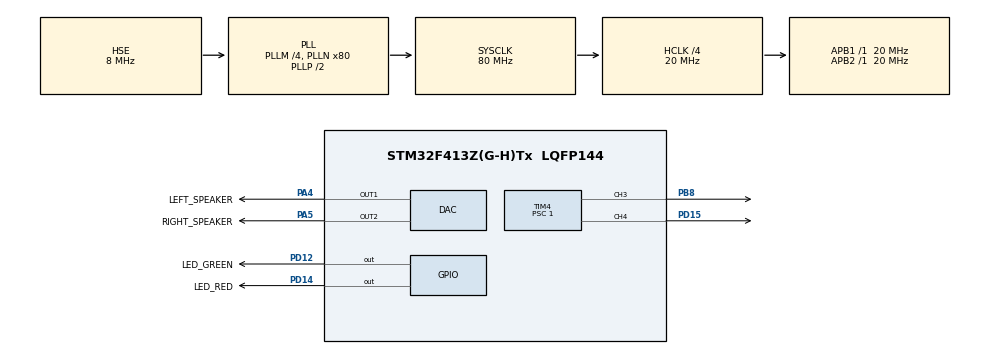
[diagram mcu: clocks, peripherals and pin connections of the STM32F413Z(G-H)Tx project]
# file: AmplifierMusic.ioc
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DAC.DAC_OutputBuffer=DAC_OUTPUTBUFFER_ENABLE
DAC.DAC_Trigger=DAC_TRIGGER_T2_TRGO
DAC.DAC_Trigger2=DAC_TRIGGER_T4_TRGO
Mcu.Family=STM32F4
Mcu.Name=STM32F413Z(G-H)Tx
Mcu.Package=LQFP144
NVIC.PriorityGroup=NVIC_PRIORITYGROUP_4
NVIC.TIM3_IRQn=true\:0\:0\:false\:false\:true\:true\:true\:true
NVIC.TIM4_IRQn=true\:0\:0\:false\:false\:true\:true\:true\:true
PA4.GPIO_Label=LEFT_SPEAKER
PA4.Signal=COMP_DAC1_group
PA5.GPIO_Label=RIGHT_SPEAKER
PA5.Signal=COMP_DAC2_group
PB8.Signal=S_TIM4_CH3
PD12.GPIO_Label=LED_GREEN
PD12.Signal=GPIO_Output
PD14.GPIO_Label=LED_RED
PD14.Signal=GPIO_Output
PD15.Signal=S_TIM4_CH4
PH0\ -\ OSC_IN.Mode=HSE-External-Oscillator
PH0\ -\ OSC_IN.Signal=RCC_OSC_IN
PH1\ -\ OSC_OUT.Mode=HSE-External-Oscillator
PH1\ -\ OSC_OUT.Signal=RCC_OSC_OUT
ProjectManager.HeapSize=0x200
ProjectManager.StackSize=0x400
ProjectManager.TargetToolchain=STM32CubeIDE
RCC.48MHZClocksFreq_Value=24000000
RCC.AHBCLKDivider=RCC_SYSCLK_DIV4
RCC.AHBFreq_Value=20000000
RCC.APB1Freq_Value=20000000
RCC.APB1TimFreq_Value=20000000
RCC.APB2Freq_Value=20000000
RCC.APB2TimFreq_Value=20000000
RCC.CortexFreq_Value=20000000
RCC.HCLKFreq_Value=20000000
RCC.HSE_VALUE=8000000
RCC.HSI_VALUE=16000000
RCC.PLLM=4
RCC.PLLMUL=RCC_PLL_MUL9
RCC.PLLN=80
RCC.PLLQ=8
RCC.PLLSourceVirtual=RCC_PLLSOURCE_HSE
RCC.PRESCALERUSB=RCC_USBCLKSOURCE_PLL_DIV1_5
RCC.SYSCLKFreq_VALUE=80000000
RCC.SYSCLKSource=RCC_SYSCLKSOURCE_PLLCLK
RCC.SYSCLKSourceVirtual=RCC_SYSCLKSOURCE_PLLCLK
RCC.USBFreq_Value=20000000
RCC.VCOOutputFreq_Value=160000000
SH.COMP_DAC1_group.0=DAC_OUT1,DAC_OUT1
SH.COMP_DAC2_group.0=DAC_OUT2,DAC_OUT2
SH.S_TIM4_CH3.0=TIM4_CH3,PWM Generation3 CH3
SH.S_TIM4_CH4.0=TIM4_CH4,PWM Generation4 CH4
TIM3.Period=\ 500
TIM3.Prescaler=1
TIM3.TIM_MasterOutputTrigger=TIM_TRGO_UPDATE
TIM4.Channel-PWM\ Generation3\ CH3=TIM_CHANNEL_3
TIM4.Channel-PWM\ Generation4\ CH4=TIM_CHANNEL_4
TIM4.OCFastMode_PWM-PWM\ Generation3\ CH3=TIM_OCFAST_ENABLE
TIM4.OCFastMode_PWM-PWM\ Generation4\ CH4=TIM_OCFAST_ENABLE
TIM4.Period=900
TIM4.Prescaler=1
TIM4.Pulse-PWM\ Generation3\ CH3=32000
TIM4.Pulse-PWM\ Generation4\ CH4=32000
VP_TIM3_VS_ClockSourceINT.Mode=Internal
VP_TIM4_VS_ClockSourceINT.Mode=Internal
board=NUCLEO-F413ZH

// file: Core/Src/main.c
/* USER CODE BEGIN Header */
/**
  ******************************************************************************
  * @file           : main.c
  * @brief          : Main program body
  ******************************************************************************
  * @attention
  *
  * Copyright (c) 2022 STMicroelectronics.
  * All rights reserved.
  *
  * This software is licensed under terms that can be found in the LICENSE file
  * in the root directory of this software component.
  * If no LICENSE file comes with this software, it is provided AS-IS.
  *
  ******************************************************************************
  */
/* USER CODE END Header */
#include "main.h"

/* USER CODE BEGIN Includes */
#include "polyphonic_tunes.h"
#include "notes.h"
#include "song_engine.h"
#include "songs.h"
/* USER CODE END Includes */

DAC_HandleTypeDef hdac;

TIM_HandleTypeDef htim3;
TIM_HandleTypeDef htim4;

/* USER CODE BEGIN PV */
music eine_kleine_nachtmusik;
/* USER CODE END PV */

void SystemClock_Config(void);
static void MX_GPIO_Init(void);
static void MX_DAC_Init(void);
static void MX_TIM3_Init(void);
static void MX_TIM4_Init(void);

/* Private user code ---------------------------------------------------------*/\
void HAL_TIM_PeriodElapsedCallback(TIM_HandleTypeDef *htim) {
	song_scheduler(htim);
}

void custom_output_channel_3_and_4(uint32_t output){
	htim4.Instance->CCR4 = output;
	htim4.Instance->CCR3 = output;
}

uint8_t custom_map_voice_channel[] = {
	TIM_CHANNEL_3,
	TIM_CHANNEL_3,
	TIM_CHANNEL_4,
	TIM_CHANNEL_4
};

int main(void)
{
  /* MCU Configuration--------------------------------------------------------*/
  /* Reset of all peripherals, Initializes the Flash interface and the Systick. */
  /* Configure the system clock */
  /* Initialize all configured peripherals */
  HAL_Init();
  SystemClock_Config();
  MX_GPIO_Init();
  MX_DAC_Init();
  MX_TIM3_Init();
  MX_TIM4_Init();

  /* fix: running tim callback */
  __HAL_TIM_CLEAR_IT(&htim3, TIM_IT_UPDATE);
  while (HAL_TIM_Base_Start_IT(&htim3) != HAL_OK) {};

  HAL_TIM_PWM_Start(&htim4, TIM_CHANNEL_4);
  HAL_TIM_PWM_Start(&htim4, TIM_CHANNEL_3);

  initialize_song_engine(80000000, &htim3);
  set_custom_output_handler(custom_output_channel_3_and_4);
  set_map_channel_voices(custom_map_voice_channel);

 //configure each independent voice
 eine_kleine_nachtmusik.voices[0] = violino1;
 eine_kleine_nachtmusik.voices[1] = violino2;
 eine_kleine_nachtmusik.voices[2] = viola;
 eine_kleine_nachtmusik.voices[3] = cello;

 //configure general music settings
 eine_kleine_nachtmusik.bpm = 120;
 eine_kleine_nachtmusik.nota_ref = QUARTER_NOTE;
 eine_kleine_nachtmusik.oitava = 4;

 //load song into memory
 load_song(eine_kleine_nachtmusik);
 HAL_TIM_PeriodElapsedCallback(&htim3);

 while (1) {
	 HAL_GPIO_TogglePin(GPIOD, LED_GREEN_Pin|LED_RED_Pin);
	 play_song();

	 while(get_song_status() != STOPPED) {
	  HAL_Delay(100);
	 };

	 stop_song();
	 HAL_GPIO_TogglePin(GPIOD, LED_GREEN_Pin|LED_RED_Pin);
 }
}

void SystemClock_Config(void)
{
  RCC_OscInitTypeDef RCC_OscInitStruct = {0};
  RCC_ClkInitTypeDef RCC_ClkInitStruct = {0};

  /** Configure the main internal regulator output voltage
  */
  __HAL_RCC_PWR_CLK_ENABLE();
  __HAL_PWR_VOLTAGESCALING_CONFIG(PWR_REGULATOR_VOLTAGE_SCALE1);

  /** Initializes the RCC Oscillators according to the specified parameters
  * in the RCC_OscInitTypeDef structure.
  */
  RCC_OscInitStruct.OscillatorType = RCC_OSCILLATORTYPE_HSE;
  RCC_OscInitStruct.HSEState = RCC_HSE_ON;
  RCC_OscInitStruct.PLL.PLLState = RCC_PLL_ON;
  RCC_OscInitStruct.PLL.PLLSource = RCC_PLLSOURCE_HSE;
  RCC_OscInitStruct.PLL.PLLM = 4;
  RCC_OscInitStruct.PLL.PLLN = 80;
  RCC_OscInitStruct.PLL.PLLP = RCC_PLLP_DIV2;
  RCC_OscInitStruct.PLL.PLLQ = 8;
  RCC_OscInitStruct.PLL.PLLR = 2;
  if (HAL_RCC_OscConfig(&RCC_OscInitStruct) != HAL_OK)
  {
    Error_Handler();
  }

  /** Initializes the CPU, AHB and APB buses clocks
  */
  RCC_ClkInitStruct.ClockType = RCC_CLOCKTYPE_HCLK|RCC_CLOCKTYPE_SYSCLK
                              |RCC_CLOCKTYPE_PCLK1|RCC_CLOCKTYPE_PCLK2;
  RCC_ClkInitStruct.SYSCLKSource = RCC_SYSCLKSOURCE_PLLCLK;
  RCC_ClkInitStruct.AHBCLKDivider = RCC_SYSCLK_DIV4;
  RCC_ClkInitStruct.APB1CLKDivider = RCC_HCLK_DIV1;
  RCC_ClkInitStruct.APB2CLKDivider = RCC_HCLK_DIV1;

  if (HAL_RCC_ClockConfig(&RCC_ClkInitStruct, FLASH_LATENCY_0) != HAL_OK)
  {
    Error_Handler();
  }
}

static void MX_DAC_Init(void)
{

  DAC_ChannelConfTypeDef sConfig = {0};

  /** DAC Initialization
  */
  hdac.Instance = DAC;
  if (HAL_DAC_Init(&hdac) != HAL_OK)
  {
    Error_Handler();
  }

  /** DAC channel OUT1 config
  */
  sConfig.DAC_Trigger = DAC_TRIGGER_T2_TRGO;
  sConfig.DAC_OutputBuffer = DAC_OUTPUTBUFFER_ENABLE;
  if (HAL_DAC_ConfigChannel(&hdac, &sConfig, DAC_CHANNEL_1) != HAL_OK)
  {
    Error_Handler();
  }

  /** DAC channel OUT2 config
  */
  sConfig.DAC_Trigger = DAC_TRIGGER_T4_TRGO;
  if (HAL_DAC_ConfigChannel(&hdac, &sConfig, DAC_CHANNEL_2) != HAL_OK)
  {
    Error_Handler();
  }
}

static void MX_TIM3_Init(void)
{

  TIM_ClockConfigTypeDef sClockSourceConfig = {0};
  TIM_MasterConfigTypeDef sMasterConfig = {0};

  htim3.Instance = TIM3;
  htim3.Init.Prescaler = 1; // best: 0-1
  htim3.Init.CounterMode = TIM_COUNTERMODE_UP;
  htim3.Init.Period = 500; // best: 500-1000. original -> 4799
  htim3.Init.ClockDivision = TIM_CLOCKDIVISION_DIV1;
  htim3.Init.AutoReloadPreload = TIM_AUTORELOAD_PRELOAD_DISABLE;
  if (HAL_TIM_Base_Init(&htim3) != HAL_OK)
  {
    Error_Handler();
  }
  sClockSourceConfig.ClockSource = TIM_CLOCKSOURCE_INTERNAL;
  if (HAL_TIM_ConfigClockSource(&htim3, &sClockSourceConfig) != HAL_OK)
  {
    Error_Handler();
  }
  sMasterConfig.MasterOutputTrigger = TIM_TRGO_RESET;
  sMasterConfig.MasterSlaveMode = TIM_MASTERSLAVEMODE_DISABLE;
  if (HAL_TIMEx_MasterConfigSynchronization(&htim3, &sMasterConfig) != HAL_OK)
  {
    Error_Handler();
  }

}

static void MX_TIM4_Init(void)
{

  TIM_ClockConfigTypeDef sClockSourceConfig = {0};
  TIM_MasterConfigTypeDef sMasterConfig = {0};
  TIM_OC_InitTypeDef sConfigOC = {0};

  htim4.Instance = TIM4;
  htim4.Init.Prescaler = 0; // 0
  htim4.Init.CounterMode = TIM_COUNTERMODE_UP;
  htim4.Init.Period = 900; // 900-1000
  htim4.Init.ClockDivision = TIM_CLOCKDIVISION_DIV1;
  htim4.Init.AutoReloadPreload = TIM_AUTORELOAD_PRELOAD_DISABLE;
  if (HAL_TIM_Base_Init(&htim4) != HAL_OK)
  {
    Error_Handler();
  }
  sClockSourceConfig.ClockSource = TIM_CLOCKSOURCE_INTERNAL;
  if (HAL_TIM_ConfigClockSource(&htim4, &sClockSourceConfig) != HAL_OK)
  {
    Error_Handler();
  }
  if (HAL_TIM_PWM_Init(&htim4) != HAL_OK)
  {
    Error_Handler();
  }
  sMasterConfig.MasterOutputTrigger = TIM_TRGO_RESET;
  sMasterConfig.MasterSlaveMode = TIM_MASTERSLAVEMODE_DISABLE;
  if (HAL_TIMEx_MasterConfigSynchronization(&htim4, &sMasterConfig) != HAL_OK)
  {
    Error_Handler();
  }
  sConfigOC.OCMode = TIM_OCMODE_PWM1;
  sConfigOC.OCPolarity = TIM_OCPOLARITY_HIGH;
  //sConfigOC.Pulse = 0;
  //sConfigOC.OCFastMode = TIM_OCFAST_DISABLE;

  sConfigOC.Pulse = 32000;
  sConfigOC.OCFastMode = TIM_OCFAST_ENABLE;
  if (HAL_TIM_PWM_ConfigChannel(&htim4, &sConfigOC, TIM_CHANNEL_3) != HAL_OK)
  {
    Error_Handler();
  }
  if (HAL_TIM_PWM_ConfigChannel(&htim4, &sConfigOC, TIM_CHANNEL_4) != HAL_OK)
  {
    Error_Handler();
  }
  HAL_TIM_MspPostInit(&htim4);

}

static void MX_GPIO_Init(void)
{
  GPIO_InitTypeDef GPIO_InitStruct = {0};

  /* GPIO Ports Clock Enable */
  __HAL_RCC_GPIOH_CLK_ENABLE();
  __HAL_RCC_GPIOA_CLK_ENABLE();
  __HAL_RCC_GPIOD_CLK_ENABLE();
  __HAL_RCC_GPIOB_CLK_ENABLE();

  /*Configure GPIO pin Output Level */
  HAL_GPIO_WritePin(GPIOD, LED_GREEN_Pin|LED_RED_Pin, GPIO_PIN_RESET);

  /*Configure GPIO pins : LED_GREEN_Pin LED_RED_Pin */
  GPIO_InitStruct.Pin = LED_GREEN_Pin|LED_RED_Pin;
  GPIO_InitStruct.Mode = GPIO_MODE_OUTPUT_PP;
  GPIO_InitStruct.Pull = GPIO_NOPULL;
  GPIO_InitStruct.Speed = GPIO_SPEED_FREQ_LOW;
  HAL_GPIO_Init(GPIOD, &GPIO_InitStruct);

}

void Error_Handler(void)
{
  __disable_irq();
  while (1)
  {
  }
}
